AUTOSAR XML (schema 00049)
package /Runnable_Lab2
  sender receiver interface SRIF_Output
    data SumResult: type=uint32
  sender receiver interface SRIF_Input
    data Val1: type=uint16
    data Val2: type=uint16
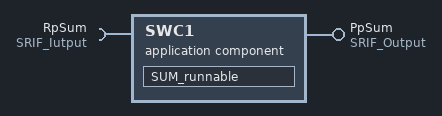
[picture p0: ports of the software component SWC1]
  application sw component type SWC1
    provide port PpSum: provided-interface=SRIF_Output
    require port RpSum: required-interface=SRIF_Iutput
    behavior SWC1_Beh
      runnable SUM_runnable: symbol=SUM
        data-read-access:
          access VAL1_DATA: accessed-variable=RpSum.Val1
          access VAL2_DATA: accessed-variable=RpSum.Val2
        data-write-access:
          access SUMResult_Data: accessed-variable=PpSum.SumResult
